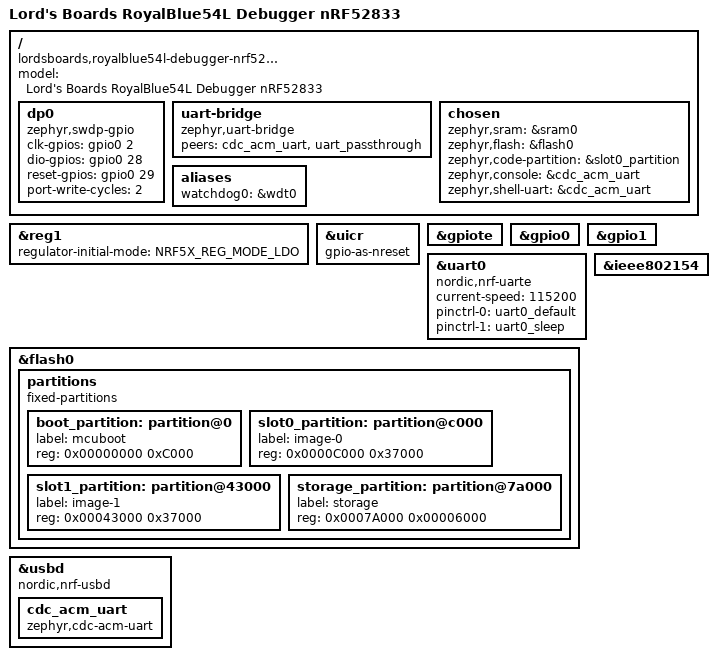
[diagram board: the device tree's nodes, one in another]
/*
 * Copyright (c) 2024 Lord's Boards LLC
 *
 * SPDX-License-Identifier: Apache-2.0
 */

/dts-v1/;
#include <nordic/nrf52833_qiaa.dtsi>
#include "royalblue54l_debugger_nrf52833-pinctrl.dtsi"

/ {
	model = "Lord's Boards RoyalBlue54L Debugger nRF52833";
	compatible = "lordsboards,royalblue54l-debugger-nrf52833";

	dp0 {
		compatible = "zephyr,swdp-gpio";
		status = "okay";
		clk-gpios = <&gpio0 2 GPIO_ACTIVE_HIGH>;
		dio-gpios = <&gpio0 28 GPIO_PULL_UP>;
		reset-gpios = <&gpio0 29 GPIO_ACTIVE_HIGH>;
		port-write-cycles = <2>;
	};

	uart-bridge {
			 compatible = "zephyr,uart-bridge";
			 peers = <&cdc_acm_uart &uart_passthrough>;
	};

	chosen {
		zephyr,sram = &sram0;
		zephyr,flash = &flash0;
		zephyr,code-partition = &slot0_partition;
		zephyr,console = &cdc_acm_uart;
		zephyr,shell-uart = &cdc_acm_uart;
	};

	aliases {
		watchdog0 = &wdt0;
	};
};

&reg1 {
	regulator-initial-mode = <NRF5X_REG_MODE_LDO>;
};

&uicr {
	gpio-as-nreset;
};

&gpiote {
	status = "okay";
};

&gpio0 {
	status = "okay";
};

&gpio1 {
	status = "okay";
};

uart_passthrough: &uart0 {
	compatible = "nordic,nrf-uarte";
	status = "okay";
	current-speed = <115200>;
	pinctrl-0 = <&uart0_default>;
	pinctrl-1 = <&uart0_sleep>;
	pinctrl-names = "default", "sleep";
};

&ieee802154 {
	status = "okay";
};

&flash0 {

	partitions {
		compatible = "fixed-partitions";
		#address-cells = <1>;
		#size-cells = <1>;

		boot_partition: partition@0 {
			label = "mcuboot";
			reg = <0x00000000 0xC000>;
		};
		slot0_partition: partition@c000 {
			label = "image-0";
			reg = <0x0000C000 0x37000>;
		};
		slot1_partition: partition@43000 {
			label = "image-1";
			reg = <0x00043000 0x37000>;
		};
		storage_partition: partition@7a000 {
			label = "storage";
			reg = <0x0007A000 0x00006000>;
		};
	};
};

zephyr_udc0: &usbd {
	compatible = "nordic,nrf-usbd";
	status = "okay";

	cdc_acm_uart: cdc_acm_uart {
		compatible = "zephyr,cdc-acm-uart";
	};
};
